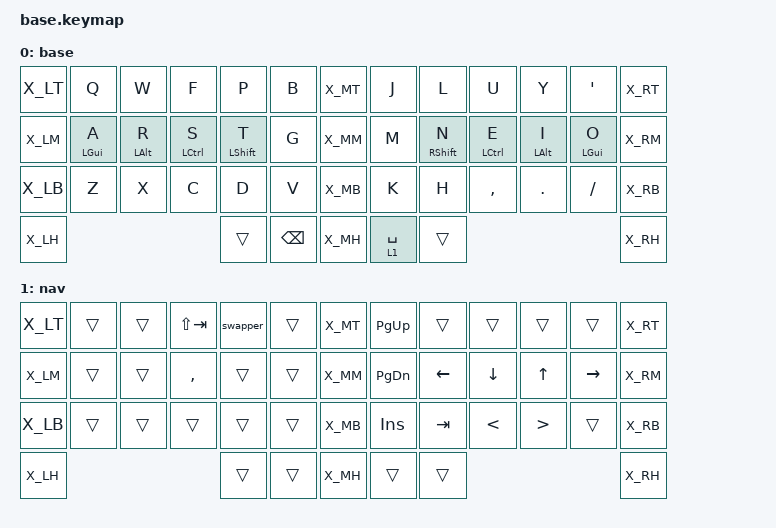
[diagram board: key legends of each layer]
/*
 * Copyright (c) 2020 The ZMK Contributors
 *
 * SPDX-License-Identifier: MIT
 */

#include <behaviors.dtsi>
#include <dt-bindings/zmk/keys.h>
#if CONFIG_WIRELESS
    #include <dt-bindings/zmk/bt.h>
    #define _BT_SEL_KEYS_ &bt BT_SEL 0 &bt BT_SEL 1 &bt BT_SEL 2 &bt BT_SEL 3 &bt BT_CLR
#else
    #define _BT_SEL_KEYS_ &trans &trans &trans &trans &trans
#endif
#include <dt-bindings/zmk/outputs.h>

#include "../zmk-nodefree-config/helper.h"
#include "extra_keys.h"

#define DEF 0
#define NAV 1

#define XXX &none
#define ___ &trans

#define _BT_SEL_KEYS_ &bt BT_SEL 0 &bt BT_SEL 1 &bt BT_SEL 2 &bt BT_SEL 3 &bt BT_CLR

/* GLOBAL SETTINGS */
#define QUICK_TAP_MS 175

&sk {  // sticky-key config
    release-after-ms = <900>;  // release after 0.6s
    quick-release;             // no double capitalization when rolling keys
};

&sl {  // sticky-layer config
    ignore-modifiers;          // allow chording sticky mods & layers
};

&lt {  // layer-tap config
    flavor = "balanced";
    tapping-term-ms = <200>;
    quick-tap-ms = <QUICK_TAP_MS>;
};

/* HOMEROW MODS */
#define KEYS_L \
    LT0 LT1 LT2 LT3 LT4 LT5 \
    LM0 LM1 LM2 LM3 LM4 LM5 \
    LB0 LB1 LB2 LB3 LB4 LB5 \
    LF0 LF1 LF2 LF3 LF4 LF5 LEC // left hand
#define KEYS_R \
    RT0 RT1 RT2 RT3 RT4 RT5 \
    RM0 RM1 RM2 RM3 RM4 RM5 \
    RB0 RB1 RB2 RB3 RB4 RB5 \
    RF0 RF1 RF2 RF3 RF4 RF5 REC // right hand
#define THUMBS LH3 LH2 LH1 LH0 RH0 RH1 RH2 RH3 // thumbs

#define MAKE_HRM(NAME, HOLD, TAP, TRIGGER_POS) \
    ZMK_BEHAVIOR(NAME, hold_tap, \
        flavor = "balanced"; \
        tapping-term-ms = <280>; \
        quick-tap-ms = <QUICK_TAP_MS>; \
        require-prior-idle-ms = <150>; \
        bindings = <HOLD>, <TAP>; \
        hold-trigger-key-positions = <TRIGGER_POS>; \
        hold-trigger-on-release; \
    )
MAKE_HRM(hml, &kp, &kp, KEYS_R THUMBS)  // left-hand HRMs
MAKE_HRM(hmr, &kp, &kp, KEYS_L THUMBS)  // right-hand HRMs

/* CUSTOM BEHAVIORS */
// Alt+Tab swapper, requires PR #1366
ZMK_BEHAVIOR(swapper, tri_state,
    bindings = <&kt LALT>, <&kp TAB>, <&kt LALT>;
    ignored-key-positions = <LT2>;
)

/* LAYERS */
ZMK_LAYER(base,
//╭──────╮ ╭─────────────┬─────────────┬─────────────┬─────────────┬─────────────╮ ╭──────╮ ╭─────────────┬─────────────┬─────────────┬─────────────┬─────────────╮ ╭──────╮
    X_LT     &kp Q         &kp W         &kp F         &kp P         &kp B           X_MT     &kp J         &kp L         &kp U         &kp Y         &kp SQT         X_RT
//├──────┤ ├─────────────┼─────────────┼─────────────┼─────────────┼─────────────┤ ├──────┤ ├─────────────┼─────────────┼─────────────┼─────────────┼─────────────┤ ├──────┤
    X_LM     &hml LGUI A   &hml LALT R   &hml LCTRL S  &hml LSHFT T  &kp G           X_MM     &kp M         &hmr RSHFT N  &hmr LCTRL E  &hmr LALT I   &hmr LGUI O     X_RM
//├──────┤ ├─────────────┼─────────────┼─────────────┼─────────────┼─────────────┤ ├──────┤ ├─────────────┼─────────────┼─────────────┼─────────────┼─────────────┤ ├──────┤
    X_LB     &kp Z         &kp X         &kp C         &kp D         &kp V           X_MB     &kp K         &kp H         &kp COMMA     &kp DOT       &kp SLASH       X_RB
//├──────┤ ╰─────────────┼─────────────┴─────────────┼─────────────┼─────────────┤ ├──────┤ ├─────────────┼─────────────┼─────────────┴───────────────────────────╯ ├──────┤
    X_LH                                               ___           &kp BSPC        X_MH     &lt 1 SPACE  ___                                                       X_RH
//╰──────╯                                           ╰─────────────┴─────────────╯ ╰──────╯ ╰─────────────┴─────────────╯                                           ╰──────╯
)

ZMK_LAYER(nav,
//╭──────╮ ╭─────────────┬─────────────┬─────────────┬─────────────┬─────────────╮ ╭──────╮ ╭─────────────┬─────────────┬─────────────┬─────────────┬─────────────╮ ╭──────╮
    X_LT     ___           ___           &kp LS(TAB)   &swapper      ___             X_MT     &kp PG_UP     ___           ___           ___           ___             X_RT
//├──────┤ ├─────────────┼─────────────┼─────────────┼─────────────┼─────────────┤ ├──────┤ ├─────────────┼─────────────┼─────────────┼─────────────┼─────────────┤ ├──────┤
    X_LM     ___           ___           &kp COMMA     ___           ___             X_MM     &kp PG_DN     &kp LEFT      &kp DOWN      &kp UP        &kp RIGHT       X_RM
//├──────┤ ├─────────────┼─────────────┼─────────────┼─────────────┼─────────────┤ ├──────┤ ├─────────────┼─────────────┼─────────────┼─────────────┼─────────────┤ ├──────┤
    X_LB     ___           ___           ___           ___           ___             X_MB     &kp INS       &kp TAB       &kp LT        &kp GT        ___             X_RB
//├──────┤ ╰─────────────┼─────────────┴─────────────┼─────────────┼─────────────┤ ├──────┤ ├─────────────┼─────────────┼─────────────┴───────────────────────────╯ ├──────┤
    X_LH                                               ___           ___             X_MH     ___           ___                                                       X_RH
//╰──────╯                                           ╰─────────────┴─────────────╯ ╰──────╯ ╰─────────────┴─────────────╯                                           ╰──────╯
)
